# SAM9X75D2G device description
Architecture: ARM926EJ-S; Family: SAM9; Series: SAM9X7
Registers are 32-bit, read-write, reset 0x0 unless marked. A register's access mark holds for its fields unless they carry their own. Offsets are from the block's base; [hi:lo] are bit positions; {n}, {i} and the like mark numbered series; <NAME> marks a mode.

## MPDDRC — AHB Multiport DDR-SDRAM Controller
Instances: MPDDRC 0xFFFFE800
0x00 MPDDRC_MR — Mode Register
  [2:0] MODE — MPDDRC Command Mode
    0=NORMAL_CMD (Normal Mode. Any access to the MPDDRC is decoded normally. To activate this mode, the command must be followed by a write to the DDR-SDRAM.); 1=NOP_CMD (The MPDDRC issues a NOP command when the DDR-SDRAM device is accessed regardless of the cycle. To activate this mode, the command must be followed by a write to the DDR-SDRAM.); 2=PRCGALL_CMD (The MPDDRC issues the All Banks Precharge command when the DDR-SDRAM device is accessed regardless of the cycle. To activate this mode, the command must be followed by a write to the SDRAM.); 3=LMR_CMD (The MPDDRC issues a Load Mode Register command when the DDR-SDRAM device is accessed regardless of the cycle. To activate this mode, the command must be followed by a write to the DDR-SDRAM.); 4=RFSH_CMD (The MPDDRC issues an Autorefresh command when the DDR-SDRAM device is accessed regardless of the cycle. Previously, an All Banks Precharge command must be issued. To activate this mode, the command must be followed by a write to the DDR-SDRAM.); 5=EXT_LMR_CMD (The MPDDRC issues an Extended Load Mode Register command when the SDRAM device is accessed regardless of the cycle. To activate this mode, the command must be followed by a write to the DDR-SDRAM. The write in the DDR-SDRAM must be done in the appropriate bank.); 6=DEEP_CALIB_MD (Deep Power mode: Access to Deep Powerdown mode Calibration command: to calibrate RTT and RON values for the Process Voltage Temperature (PVT) (DDR3-SDRAM device))
0x04 MPDDRC_RTR — Refresh Timer Register
  [11:0] COUNT — MPDDRC Refresh Timer Count
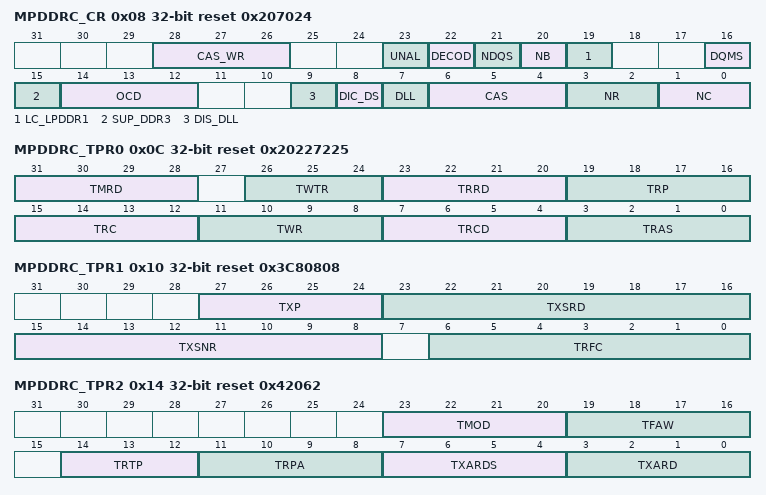
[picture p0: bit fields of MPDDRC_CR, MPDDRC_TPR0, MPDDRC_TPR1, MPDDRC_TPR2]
0x08 MPDDRC_CR reset 0x207024 — Configuration Register
  [28:26] CAS_WR — CAS Write Latency
    5=DDR3_CAS5 (DDR3 CAS write latency 5, DLL must be enabled, DLL On mode); 6=DDR3_CAS6 (DDR3 CAS write latency 6, DLL enabled or not, DLL On/Off mode)
  [23] UNAL — This bit must always be written to 1
  [22] DECOD — Type of Decoding
    0=SEQUENTIAL (Method for address mapping where banks alternate at each last DDR-SDRAM page of the current bank.); 1=INTERLEAVED (Method for address mapping where banks alternate at each DDR-SDRAM end of page of the current bank.)
  [21] NDQS — Not DQS.
    0=ENABLED ('Not DQS' is enabled.); 1=DISABLED ('Not DQS' is disabled.)
  [20] NB — Number of Banks
    0=4_BANKS (4-bank memory devices); 1=8_BANKS (8 banks. Only possible when using DDR2-SDRAMand DDR3-SDRAM devices.)
  [19] LC_LPDDR1 — Low-cost Low-power DDR1
    0=NOT_2_BANKS (Any type of memory devices except of low cost, low density Low Power DDR1.); 1=2_BANKS_LPDDR1 (Low-cost and low-density low-power DDR1. These devices have a density of 32 Mbits and are organized as two internal banks. To use this feature, the user has to define the type of memory and the data bus width (see Section 8.8 "MPDDRC Memory Device Register"). The 16-bit memory device is organized as 2 banks, 9 columns and 11 rows.)
  [16] DQMS — Mask Data is Shared
    0=NOT_SHARED (DQM is not shared with another controller); 1=SHARED (DQM is shared with another controller)
  [15] SUP_DDR3 — Supply DDR3-SDRAM or DDR3L-SDRAM
    0=1.35V DDR3L-SDRAM is used; 1=1.5V DDR3-SDRAM is used
  [14:12] OCD — Off-chip Driver
    0=DDR2_EXITCALIB (Exit from OCD Calibration mode and maintain settings); 7=DDR2_DEFAULT_CALIB (OCD calibration default)
  [9] DIS_DLL — Disable DLL
    0=Enable DLL; 1=Disable DLL
  [8] DIC_DS — Output Driver Impedance Control (Drive Strength)
    0=DDR2_NORMALSTRENGTH_DDR3_RZQ_6 (Normal drive strength (DDR2)- RZQ_6 (40 [NOM], DDR3)); 1=DDR2_WEAKSTRENGTH_DDR3_RZQ_7 (Weak drive strength (DDR2)- RZQ_7 (34 [NOM], DDR3))
  [7] DLL — Reset DLL
    0=RESET_DISABLED (Disable DLL reset); 1=RESET_ENABLED (Enable DLL reset)
  [6:4] CAS — CAS Latency
    2=DDR_CAS2 (LPDDR1 CAS Latency 2); 3=DDR_CAS3 (DDR2/LPDDR1 CAS Latency 3); 4=DDR_CAS4 (DDR2 CAS Latency 4); 5=DDR_CAS5 (DDR2/DDR3 CAS Latency 5); 6=DDR_CAS6 (DDR2/DDR3 CAS Latency 6)
  [3:2] NR — Number of Row Bits
    0=11_ROW_BITS (11 bits to define the row number, up to 2048 rows); 1=12_ROW_BITS (12 bits to define the row number, up to 4096 rows); 2=13_ROW_BITS (13 bits to define the row number, up to 8192 rows); 3=14_ROW_BITS (14 bits to define the row number, up to 16384 rows)
  [1:0] NC — Number of Column Bits
    0=DDR9_MDDR8_COL_BITS (9 bits to define the column number, up to 512 columns, for DDR2/DDR3-SDRAM 8 bits to define the column number, up to 256 columns, for LPDDR1-SDRAM); 1=DDR10_MDDR9_COL_BITS (10 bits to define the column number, up to 1024 columns, for DDR2/DDR3-SDRAM 9 bits to define the column number, up to 512 columns, for LPDDR1-SDRAM); 2=DDR11_MDDR10_COL_BITS (11 bits to define the column number, up to 2048 columns, for DDR2/DDR3-SDRAM 10 bits to define the column number, up to 1024 columns, for LPDDR1-SDRAM); 3=DDR12_MDDR11_COL_BITS (12 bits to define the column number, up to 4096 columns, for DDR2/DDR3-SDRAM 11 bits to define the column number, up to 2048 columns, for LPDDR1-SDRAM)
0x0C MPDDRC_TPR0 reset 0x20227225 — Timing Parameter 0 Register
  [31:28] TMRD — Load Mode Register Command to Activate or Refresh Command
  [26:24] TWTR — Internal Write to Read Delay
  [23:20] TRRD — Active BankA to Active BankB
  [19:16] TRP — Row Precharge Delay
  [15:12] TRC — Row Cycle Delay
  [11:8] TWR — Write Recovery Delay
  [7:4] TRCD — Row to Column Delay
  [3:0] TRAS — Active to Precharge Delay
0x10 MPDDRC_TPR1 reset 0x3C80808 — Timing Parameter 1 Register
  [27:24] TXP — Exit Powerdown Delay to First Command
  [23:16] TXSRD — Exit Self-refresh Delay to Read Command
  [15:8] TXSNR — Exit Self-refresh Delay to Non-Read Command
  [6:0] TRFC — Row Refresh Cycle
0x14 MPDDRC_TPR2 reset 0x42062 — Timing Parameter 2 Register
  [23:20] TMOD — Mode Register Set Command Update Delay
  [19:16] TFAW — Four Active Windows
  [14:12] TRTP — Read to Precharge
  [11:8] TRPA — Row Precharge All Delay
  [7:4] TXARDS — Exit Active Power Down Delay to Read Command in Mode "Slow Exit"
  [3:0] TXARD — Exit Active Power Down Delay to Read Command in Mode "Fast Exit"
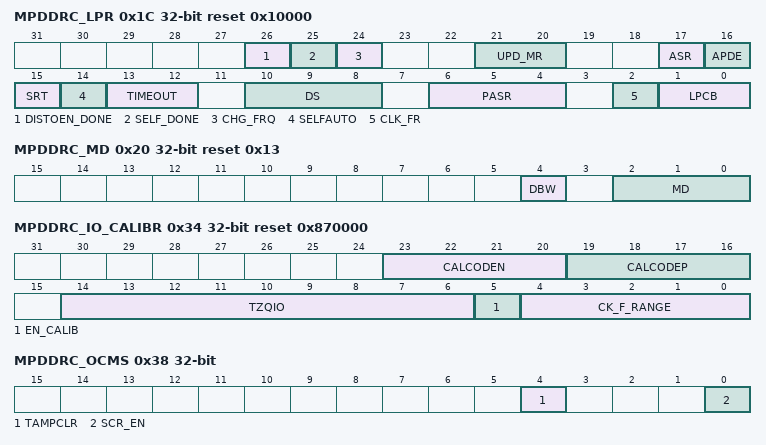
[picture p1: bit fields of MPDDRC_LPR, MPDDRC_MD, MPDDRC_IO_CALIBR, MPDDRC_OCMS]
0x1C MPDDRC_LPR reset 0x10000 — Low-Power Register
  [26] DISTOEN_DONE — DLL Disabled to DLL Enabled is Done (read-only)
  [25] SELF_DONE — Self-refresh is Done (read-only)
  [24] CHG_FRQ — Change Clock Frequency During Self-refresh Mode
  [21:20] UPD_MR — Update Load Mode Register and Extended Mode Register
    0=NO_UPDATE (Update of Load Mode and Extended Mode registers is disabled.); 1=UPDATE_SHAREDBUS (MPDDRC shares an external bus. Automatic update is done during a refresh command and a pending read or write access in the SDRAM device.); 2=UPDATE_NOSHAREDBUS (MPDDRC does not share an external bus. Automatic update is done before entering Self-refresh mode.)
  [17] ASR — Auto Self-refresh
    0=Manual Self-refresh reference must be applied; 1=DRAM manages Self-refresh entry in either the normal or extended temperature range. In this mode, DRAM manages Self-refresh power consumption when operating conditions change - lower at low temperatures and higher at high temperatures.
  [16] APDE — Active Power Down Exit Time
    0=DDR2_FAST_EXIT (Fast Exit from Power Down. DDR2-SDRAM and DDR3-SDRAM devices only.); 1=DDR2_SLOW_EXIT (Slow Exit from Power Down. DDR2-SDRAM and DDR3-SDRAM devices only.)
  [15] SRT — High Temperature Self-refresh Rate
    0=1x refresh rate. Industrial and automative devices with temperatures that do not exceed 85\xfb C.; 1=2x refresh rate. Provides a faster rate on industrial and automotive devices if temperature exceeds 85\xfb C.
  [14] SELFAUTO — Self-refresh Exit Autorefresh
    0=Upon exiting Self-refresh mode, active command is immediately performed after tXSNR. The autorefresh command is issued every 15.6 \xb5 s or less.; 1=Upon exiting Self-refresh mode, autorefresh command is immediately performed after tXSNR
  [13:12] TIMEOUT — Time Between Last Transfer and Low-Power Mode
    0=NONE (SDRAM Low-power mode is activated immediately after the end of the last transfer.); 1=DELAY_64_CLK (SDRAM Low-power mode is activated 64 clock cycles after the end of the last transfer.); 2=DELAY_128_CLK (SDRAM Low-power mode is activated 128 clock cycles after the end of the last transfer.)
  [10:8] DS — Drive Strength
    0=DS_FULL (Full drive strength); 1=DS_HALF (Half drive strength); 2=DS_QUARTER (Quarter drive strength); 3=DS_OCTANT (Octant drive strength)
  [6:4] PASR — Partial Array Self-refresh
  [2] CLK_FR — Clock Frozen Command Bit
    0=DISABLED (Clock(s) is/are not frozen.); 1=ENABLED (Clock(s) is/are frozen.)
  [1:0] LPCB — Low-power Command Bit
    0=NOLOWPOWER (Low-power feature is inhibited. No Powerdown, Self-refresh and Deep power modes are issued to the DDR-SDRAM device.); 1=SELFREFRESH (The MPDDRC issues a self-refresh command to the DDR-SDRAM device, the clock(s) is/are deactivated and the CKE signal is set low. The DDR-SDRAM device leaves the Self-refresh mode when accessed and reenters it after the access.); 2=POWERDOWN (The MPDDRC issues a Powerdown command to the DDR-SDRAM device after each access, the CKE signal is set low. The DDR-SDRAM device leaves the Powerdown mode when accessed and reenters it after the access.); 3=DEEPPOWERDOWN (The MPDDRC issues a Deep Powerdown command to the low-power DDR-SDRAM device.)
0x20 MPDDRC_MD reset 0x13 — Memory Device Register
  [4] DBW — Data Bus Width
    1=DBW_16_BITS (Data bus width is 16 bits.)
  [2:0] MD — Memory Device
    3=LPDDR_SDRAM (Low-power DDR1-SDRAM); 4=DDR3_SDRAM; 6=DDR2_SDRAM
0x2C MPDDRC_DDR3_CAL — DDR3 Calibration Register
  [15:0] COUNT_CAL — DDR3 Calibration Timer Count
0x30 MPDDRC_DDR3_TIM_CAL reset 0x6 — DDR3 Timing Calibration Register
  [7:0] ZQCS — ZQ Calibration Short
0x34 MPDDRC_IO_CALIBR reset 0x870000 — I/O Calibration Register
  [23:20] CALCODEN — Number of N-type Transistors (read-only)
  [19:16] CALCODEP — Number of P-type Transistors (read-only)
  [14:6] TZQIO — IO Calibration
  [5] EN_CALIB — Enable Calibration
    0=DISABLE_CALIBRATION (Calibration is disabled.); 1=ENABLE_CALIBRATION (Calibration is enabled.)
  [4:0] CK_F_RANGE — DDRCK Maximum Clock Frequency Range Indicator
0x38 MPDDRC_OCMS — OCMS Register
  [4] TAMPCLR — Tamper Clear Enable
    0=A tamper detection event has no effect on MPDDRC scrambling keys; 1=A tamper detection event immediately clears MPDDRC scrambling keys
  [0] SCR_EN — Scrambling Enable
    0=Disables "Off-chip" scrambling for SDRAM access; 1=Enables "Off-chip" scrambling for SDRAM access
0x3C MPDDRC_OCMS_KEY1 wo reset not defined — OCMS KEY1 Register
  [31:0] KEY1 — Off-chip Memory Scrambling (OCMS) Key Part 1
0x40 MPDDRC_OCMS_KEY2 wo reset not defined — OCMS KEY2 Register
  [31:0] KEY2 — Off-chip Memory Scrambling (OCMS) Key Part 2
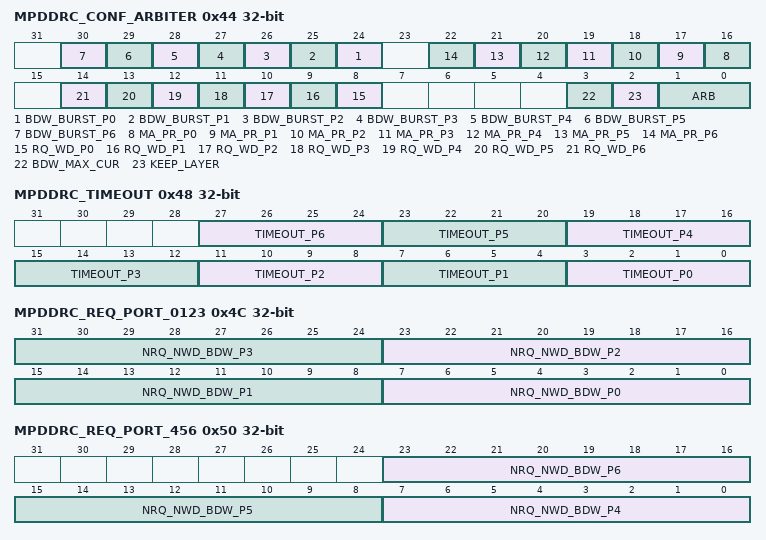
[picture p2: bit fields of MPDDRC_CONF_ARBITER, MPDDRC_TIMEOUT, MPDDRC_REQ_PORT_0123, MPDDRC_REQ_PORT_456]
0x44 MPDDRC_CONF_ARBITER — Configuration Arbiter Register
  [n+24] BDW_BURST_P{n} (n=0..6) — Bandwidth Arbitration Mode on Port X
    0=The arbitration is done when the bandwidth limit defined in MPDDRC_BDW_PORT_0123/456.BDW_Px is reached. If the bandwidth limit is reached during a burst access, the burst is completed.; 1=The arbitration is done when the bandwidth limit defined in MPDDRC_BDW_PORT_0123/456.BDW_Px is reached. If the bandwidth limit is reached during a burst access, the burst is broken.
  [n+16] MA_PR_P{n} (n=0..6) — Host or Software Provide Information
    0=Number of requests or words is provided by the host, if the host supports this feature; 1=Number of requests or words is provided by software, see "NRQ_NWD_BDW_Px: Number of Requests, Number of Words or Bandwidth Allocation from Port 0-1-2-3"
  [n+8] RQ_WD_P{n} (n=0..6) — Request or Word from Port X
    0=Number of requests is selected; 1=Number of words is selected
  [3] BDW_MAX_CUR — Bandwidth Max or Current
    0=Current bandwidth is displayed; 1=Maximum of the bandwidth is displayed
  [2] KEEP_LAYER — Layer (Port) Kept by Host
    0=No impact on arbitration scheme; 1=Some hosts, such as LCD or DMA, drive a signal named HNBREQ on the system bus to indicate the number of transfers to be performed. The host with the highest LQOS value and a HNBREQ value different from 0 continues to be granted, even during a last data phase with IDLE cycles. This function is effective if the type of arbitration is LQOS.
  [1:0] ARB — Type of Arbitration
    0=ROUND (Round-Robin Policy); 1=NB_REQUEST (Request Policy); 2=BANDWIDTH (Bandwidth Policy); 3=LQOS (Quality of Service Policy)
0x48 MPDDRC_TIMEOUT — Timeout Register
  [4n+3:4n] TIMEOUT_P{n} (n=0..6) — Timeout for Ports 0, 1, 2, 3, 4, 5, 6
0x4C MPDDRC_REQ_PORT_0123 — Request Port 0-1-2-3 Register
  [8n+7:8n] NRQ_NWD_BDW_P{n} (n=0..3) — Number of Requests, Number of Words or Bandwidth Allocation from Port 0-1-2-3
0x50 MPDDRC_REQ_PORT_456 — Request Port 4-5-6 Register
  [23:16] NRQ_NWD_BDW_P6 — Number of Requests, Number of Words or Bandwidth allocation from port 4-5-6
  [15:8] NRQ_NWD_BDW_P5 — Number of Requests, Number of Words or Bandwidth allocation from port 4-5-6
  [7:0] NRQ_NWD_BDW_P4 — Number of Requests, Number of Words or Bandwidth allocation from port 4-5-6
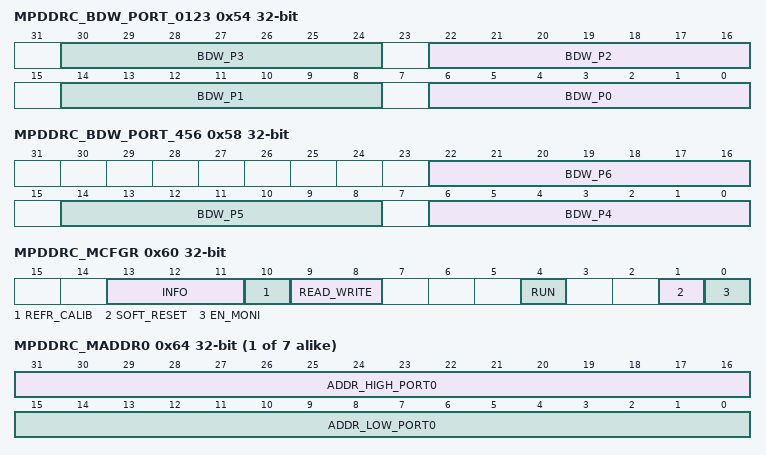
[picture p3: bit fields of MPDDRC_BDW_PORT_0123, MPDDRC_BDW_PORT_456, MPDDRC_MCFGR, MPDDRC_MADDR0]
0x54 MPDDRC_BDW_PORT_0123 ro — Current/Maximum Bandwidth Port 0-1-2-3 Register
  [8n+6:8n] BDW_P{n} (n=0..3) — Current/Maximum Bandwidth from Port 0-1-2-3
0x58 MPDDRC_BDW_PORT_456 ro — Current/Maximum Bandwidth Port 4-5-6 Register
  [22:16] BDW_P6 — Current/Maximum Bandwidth from Port 4-5-6
  [14:8] BDW_P5 — Current/Maximum Bandwidth from Port 4-5-6
  [6:0] BDW_P4 — Current/Maximum Bandwidth from Port 4-5-6
0x5C MPDDRC_RD_DATA_PATH — Read Data Path Register
  [1:0] SHIFT_SAMPLING — Shift Sampling Point of Data
    0=NO_SHIFT (Initial sampling point.); 1=SHIFT_ONE_CYCLE (Sampling point is shifted by one cycle.); 2=SHIFT_TWO_CYCLES (Sampling point is shifted by two cycles.); 3=SHIFT_THREE_CYCLES (Sampling point is shifted by three cycles, unique for DDR2 and DDR3. Not applicable for LPDDR1devices)
0x60 MPDDRC_MCFGR — Monitor Configuration Register
  [13:11] INFO — Information Type
    0=MAX_WAIT (Information concerning the transfer with the longest waiting time); 1=NB_TRANSFERS (Number of transfers on the port); 2=TOTAL_LATENCY (Total latency on the port); 4=MAX_WAIT_QOS01 (Information concerning the transfer with the longest waiting time, depending on QOS values (0 and 1)); 5=MAX_WAIT_QOS23 (Information concerning the transfer with the longest waiting time, depending on QOS values (2 and 3)); 6=TOTAL_CYCLE_COUNT (Indicates the total number of cycles from beginning to end of monitoring.)
  [10] REFR_CALIB — Refresh Calibration
    0=Monitoring does not depend on Autorefresh mode, Self-refresh mode, Powerdown mode, DLL nor calibration impact; 1=Monitoring depends on Autorefresh mode, Self-refresh mode, Powerdown mode, DLL and calibration impact./mi/m
  [9:8] READ_WRITE — Read/Write Access
    0=TRIG_RD_WR (Read and Write accesses are triggered.); 1=TRIG_WR (Only Write accesses are triggered.); 2=TRIG_RD (Only Read accesses are triggered.)
  [4] RUN — Control Monitor
    0=Monitoring is halted. All counters are stopped.; 1=Monitoring is launched
  [1] SOFT_RESET
    0=Soft reset is not performed; 1=Soft reset is performed
  [0] EN_MONI — Enable Monitor
    0=Monitor is disabled; 1=Monitor is enabled
{0x64+4i} MPDDRC_MADDR{i} (i=0..6) — Monitor Address High/Low Port {i} Register
  [31:16] ADDR_HIGH_PORT{i} — Address High on Port [x = 0..6]
  [15:0] ADDR_LOW_PORT{i} — Address Low on Port [x = 0..6]
{0x84+4i} MPDDRC_MINFO{i} ro (i=0..6) — Monitor Information Port {i} Register
  [26:25] LQOS <MAX_WAIT> — Value of Quality Of Service on Port [x = 0..6]
    0=BACKGROUND (Background transfers); 1=BANDWIDTH (Bandwidth sensitive); 2=SENSITIVE_LAT (Latency sensitive); 3=CRITICAL_LAT (Latency critical)
  [24] READ_WRITE <MAX_WAIT> — Read or Write Access on Port [x = 0..6]
    0=Read transfer; 1=Write transfer
  [22:20] SIZE <MAX_WAIT> — Transfer Size on Port [x = 0..6]
    0=8BITS (Byte transfer); 1=16BITS (Halfword transfer); 2=32BITS (Word transfer); 3=64BITS (Dword transfer)
  [18:16] BURST <MAX_WAIT> — Type of Burst on Port [x = 0..6]
    0=SINGLE (Single transfer); 1=INCR (Incrementing burst of unspecified length); 2=WRAP4 (4-beat wrapping burst); 3=INCR4 (4-beat incrementing burst); 4=WRAP8 (8-beat wrapping burst); 5=INCR8 (8-beat incrementing burst); 6=WRAP16 (16-beat wrapping burst); 7=INCR16 (16-beat incrementing burst)
  [15:0] MAX_PORT{i}_WAITING <MAX_WAIT> — Address High on Port [x = 0..6]
  [31:0] P{i}_NB_TRANSFERS <NB_TRANSFERS> — Number of Transfers on Port [x = 0..6]
  [31:0] TOTAL_CYCLE_COUNT <TOTAL_CYCLE_COUNT>
  [31:0] P{i}_TOTAL_LATENCY <TOTAL_LATENCY> — Total Latency on Port [x = 0..6]
  [31:16] P{i}_TOTAL_LATENCY_QOS1 <TOTAL_LATENCY_QOS01> — Total Latency on Port [x = 0..6] when value of qos is 1
  [15:0] P{i}_TOTAL_LATENCY_QOS0 <TOTAL_LATENCY_QOS01> — Total Latency on Port [x = 0..6] when value of qos is 0
  [31:16] P{i}_TOTAL_LATENCY_QOS3 <TOTAL_LATENCY_QOS23> — Total Latency on Port [x = 0..6] when value of qos is 3
  [15:0] P{i}_TOTAL_LATENCY_QOS2 <TOTAL_LATENCY_QOS23> — Total Latency on Port [x = 0..6] when value of qos is 2
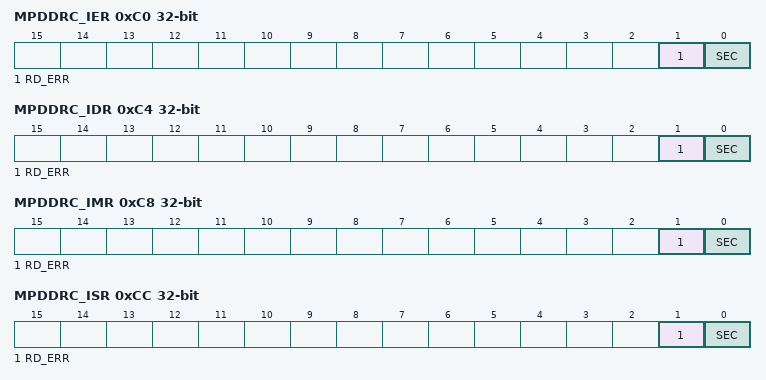
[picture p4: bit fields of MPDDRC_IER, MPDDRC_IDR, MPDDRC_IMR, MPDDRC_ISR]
0xC0 MPDDRC_IER wo reset not defined (atomic set of MPDDRC_IMR) — Interrupt Enable Register
  [1] RD_ERR — Read Error Interrupt Enable
  [0] SEC — Security and /or Safety Interrupt Enable
0xC4 MPDDRC_IDR wo reset not defined (atomic clear of MPDDRC_IMR) — Interrupt Disable Register
  [1] RD_ERR — Read Error Interrupt Disable
  [0] SEC — Security and /or Safety Interrupt Disable
0xC8 MPDDRC_IMR ro reset not defined — Interrupt Mask Register
  [1] RD_ERR — Read Error Interrupt Mask
  [0] SEC — Security and /or Safety Interrupt Mask
0xCC MPDDRC_ISR ro reset not defined — Interrupt Status Register
  [1] RD_ERR — Read Error
    0=There is no error during memory check; 1=There is one error during memory check
  [0] SEC — Security and /or Safety Event
    0=There is no security report in MPDDRC_WPSR; 1=One security flag is set in MPDDRC_WPSR
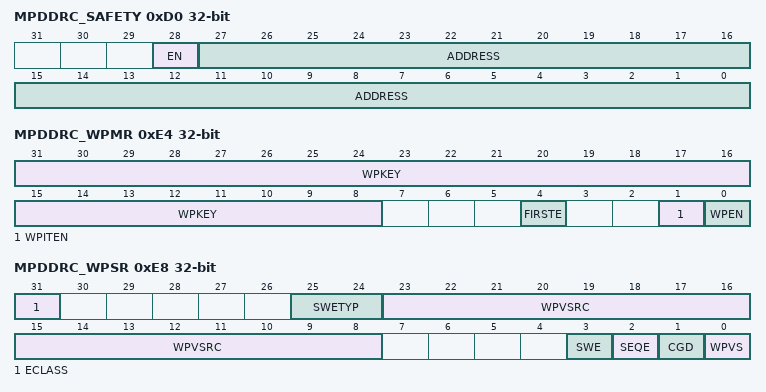
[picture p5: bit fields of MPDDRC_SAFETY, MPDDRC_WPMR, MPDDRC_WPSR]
0xD0 MPDDRC_SAFETY — Safety Register
  [28] EN — Enable Periodic Check of Memory Device
    0=Memory check is disabled; 1=Memory check is enabled
  [27:0] ADDRESS — Memory Device Address
0xE4 MPDDRC_WPMR — Write Protection Mode Register
  [31:8] WPKEY — Write Protection Key
    0x444452=PASSWD (Writing any other value in this field aborts the write operation of the WPEN and WPITEN bits. Always reads as 0.)
  [4] FIRSTE — First Error Report Enable
    0=The last write protection violation source is reported in MPDDRC_WPSR.WPVSRC and the last software control error type is reported in MPDDRC_WPSR.SWETYP. The MPDDRC_ISR.SEC flag is set at the first error occurrence within a series.; 1=Only the first write protection violation source is reported in MPDDRC_WPSR.WPVSRC and only the first software control error type is reported in MPDDRC_WPSR.SWETYP. The MPDDRC_ISR.SEC flag is set at the first error occurrence within a series.
  [1] WPITEN — Write Protection Interruption Enable
    0=Disables the write protection on interrupt registers if WPKEY corresponds to 0x444452 ("DDR" in ASCII); 1=Enables the write protection on interrupt registers if WPKEY corresponds to 0x444452 ("DDR" in ASCII)
  [0] WPEN — Write Protection Enable
    0=Disables the write protection if WPKEY corresponds to 0x444452 ("DDR" in ASCII); 1=Enables the write protection if WPKEY corresponds to 0x444452 ("DDR" in ASCII)
0xE8 MPDDRC_WPSR ro — Write Protection Status Register
  [31] ECLASS — Software Error Class (cleared on read)
    0=WARNING (An abnormal access that does not affect system functionality is performed.); 1=ERROR (An access is performed into some registers after memory device initialization sequence.)
  [25:24] SWETYP — Software Error Type (cleared on read)
    0=READ_WO (A write-only register has been read (warning).); 1=WRITE_RO (MPDDRC is enabled and a write access has been performed on a read-only register (warning).); 2=UNDEF_RW (Access to an undefined address (warning).); 3=W_AFTER_INIT (Abnormal use of MPDDRC user interface when memory device is already configured and initialized, i.e., if MPDDRC_RTR.COUNT > 0 (error).)
  [23:8] WPVSRC — Write Protection Violation Source
  [3] SWE — Software Control Error (cleared on read)
    0=No software error has occurred since the last read of MPDDRC_WPSR; 1=A software error has occurred since the last read of MPDDRC_WPSR. The field SWE details the type of software error. The associated incorrect software access is reported in the field WPVSRC (if WPVS=0).
  [2] SEQE — Internal Sequencer Error (cleared on read)
    0=No peripheral internal sequencer error has occurred since the last read of MPDDRC_WPSR; 1=A peripheral internal sequencer error has occurred since the last read of MPDDRC_WPSR. This flag can only be set under abnormal operating conditions.
  [1] CGD — Clock Glitch Detected (cleared on read)
    0=The clock monitoring circuitry has not been corrupted since the last read of MPDDRC_WPSR. Under normal operating conditions, this bit is always cleared.; 1=The clock monitoring circuitry has been corrupted since the last read of MPDDRC_WPSR. This flag can only be set in case of an abnormal clock signal waveform (glitch).
  [0] WPVS — Write Protection Enable
    0=No write protection violation occurred since the last read of this register (MPDDRC_WPSR); 1=A write protection violation occurred since the last read of this register (MPDDRC_WPSR). If this violation is an unauthorized attempt to write a control register, the associated violation is reported into the WPVSRC field.

## Notices in the file
Copyright (c) 2021 Microchip Technology Inc.
SPDX-License-Identifier: Apache-2.0
Licensed under the Apache License, Version 2.0 (the "License");
you may not use this file except in compliance with the License.
You may obtain a copy of the License at
http://www.apache.org/licenses/LICENSE-2.0
Unless required by applicable law or agreed to in writing, software
distributed under the License is distributed on an "AS IS" BASIS,
WITHOUT WARRANTIES OR CONDITIONS OF ANY KIND, either express or implied.
See the License for the specific language governing permissions and
limitations under the License.
